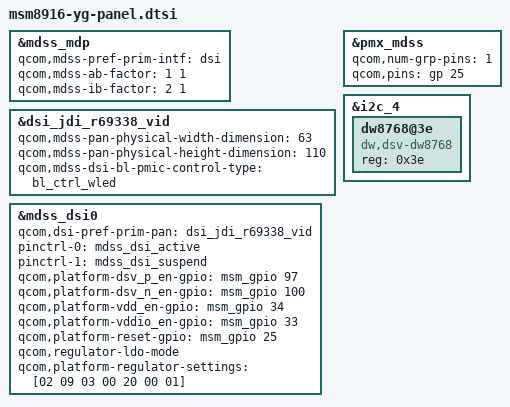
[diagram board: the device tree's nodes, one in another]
/* Copyright (c) 2013, Code Aurora Forum. All rights reserved.
 *
 * This program is free software; you can redistribute it and/or modify
 * it under the terms of the GNU General Public License version 2 and
 * only version 2 as published by the Free Software Foundation.
 *
 * This program is distributed in the hope that it will be useful,
 * but WITHOUT ANY WARRANTY; without even the implied warranty of
 * MERCHANTABILITY or FITNESS FOR A PARTICULAR PURPOSE.  See the
 * GNU General Public License for more details.
 */

#include "../msm8916-lge-common/dsi-panel-jdi-hd-video.dtsi"

&mdss_mdp {
       qcom,mdss-pref-prim-intf = "dsi";
       qcom,mdss-ab-factor = <1 1>;
       qcom,mdss-ib-factor = <2 1>;
};

&dsi_jdi_r69338_vid {
       qcom,mdss-pan-physical-width-dimension = <63>;
       qcom,mdss-pan-physical-height-dimension = <110>;
       qcom,mdss-dsi-bl-pmic-control-type = "bl_ctrl_wled";
};

&pmx_mdss {
       qcom,num-grp-pins = <1>;
       qcom,pins = <&gp 25>;
};

&mdss_dsi0 {
       qcom,dsi-pref-prim-pan = <&dsi_jdi_r69338_vid>;
       pinctrl-names = "mdss_default", "mdss_sleep";
       pinctrl-0 = <&mdss_dsi_active>;
       pinctrl-1 = <&mdss_dsi_suspend>;

	   qcom,platform-dsv_p_en-gpio = <&msm_gpio 97 0>;
	   qcom,platform-dsv_n_en-gpio = <&msm_gpio 100 0>;
	   qcom,platform-vdd_en-gpio = <&msm_gpio 34 0>;
	   qcom,platform-vddio_en-gpio = <&msm_gpio 33 0>;

       qcom,platform-reset-gpio = <&msm_gpio 25 0>;
       qcom,regulator-ldo-mode;
       qcom,platform-regulator-settings = [02 09 03 00 20 00 01];
};

&i2c_4 {
	dw8768@3e {
		compatible = "dw,dsv-dw8768";
		status = "ok";
		reg = <0x3e>;
	};
};

